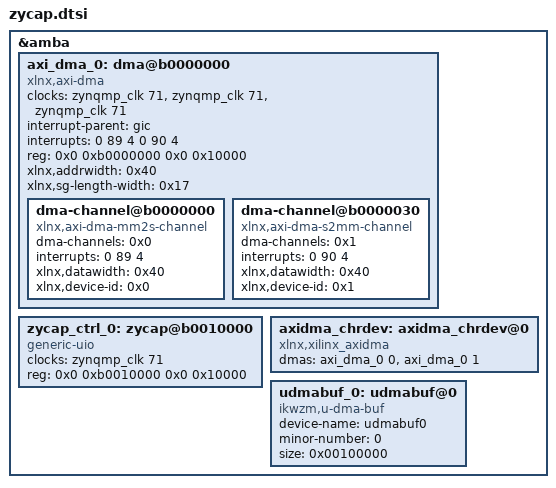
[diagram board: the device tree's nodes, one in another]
/*
 * CAUTION: This file is automatically generated by Xilinx.
 * Version: XSCT 2019.2
 * Today is: Fri Mar 12 11:06:24 2021
 */


/dts-v1/;
/plugin/;
/ {
	fragment@0 {
		target = <&amba>;
		overlay0: __overlay__ {
			#address-cells = <2>;
			#size-cells = <2>;
			axi_dma_0: dma@b0000000 {
				#dma-cells = <1>;
				clock-names = "s_axi_lite_aclk", "m_axi_mm2s_aclk", "m_axi_s2mm_aclk";
				clocks = <&zynqmp_clk 71>, <&zynqmp_clk 71>, <&zynqmp_clk 71>;
				compatible = "xlnx,axi-dma","xlnx,axi-dma-7.1", "xlnx,axi-dma-1.00.a";
				interrupt-names = "mm2s_introut", "s2mm_introut";
				interrupt-parent = <&gic>;
				interrupts = <0 89 4 0 90 4>;
				reg = <0x0 0xb0000000 0x0 0x10000>;
				xlnx,addrwidth = <0x40>;
				xlnx,sg-length-width = <0x17>;
				dma-channel@b0000000 {
					compatible = "xlnx,axi-dma-mm2s-channel";
					dma-channels = <0x0>;
					interrupts = <0 89 4>;
					xlnx,datawidth = <0x40>;
					xlnx,device-id = <0x0>;
				};
				dma-channel@b0000030 {
					compatible = "xlnx,axi-dma-s2mm-channel";
					dma-channels = <0x1>;
					interrupts = <0 90 4>;
					xlnx,datawidth = <0x40>;
					xlnx,device-id = <0x1>;
				};
			};
			// pr_wrapper_0: pr_wrapper@b0020000 {
			// 	/* This is a place holder node for a custom IP, user may need to update the entries */
			// 	clock-names = "ap_clk_0", "ap_clk_1";
			// 	clocks = <&zynqmp_clk 71>, <&zynqmp_clk 71>;
			// 	compatible = "generic-uio";
			// 	interrupt-names = "interrupt_0", "interrupt_1";
			// 	interrupt-parent = <&gic>;
			// 	interrupts = <0 92 4 0 91 4>;
			// 	reg = <0x0 0xb0020000 0x0 0x10000 0x0 0xb0030000 0x0 0x10000>;
			// };
			zycap_ctrl_0: zycap@b0010000 {
				/* This is a place holder node for a custom IP, user may need to update the entries */
				clock-names = "s_axi_lite_aclk";
				clocks = <&zynqmp_clk 71>;
				compatible = "generic-uio";
				reg = <0x0 0xb0010000 0x0 0x10000>;
			};
		};
	};
    fragment@1 {
        target = <&amba>;
        overlay1: __overlay__ {
            axidma_chrdev: axidma_chrdev@0 {
                compatible = "xlnx,xilinx_axidma";
                dmas = <&axi_dma_0 0 &axi_dma_0 1>;
                dma-names = "tx_channel", "rx_channel";
            };
            udmabuf_0: udmabuf@0 {
                compatible = "ikwzm,u-dma-buf";
                device-name = "udmabuf0";
                minor-number = <0>;
                size = <0x00100000>;
            };
        };
	};
};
